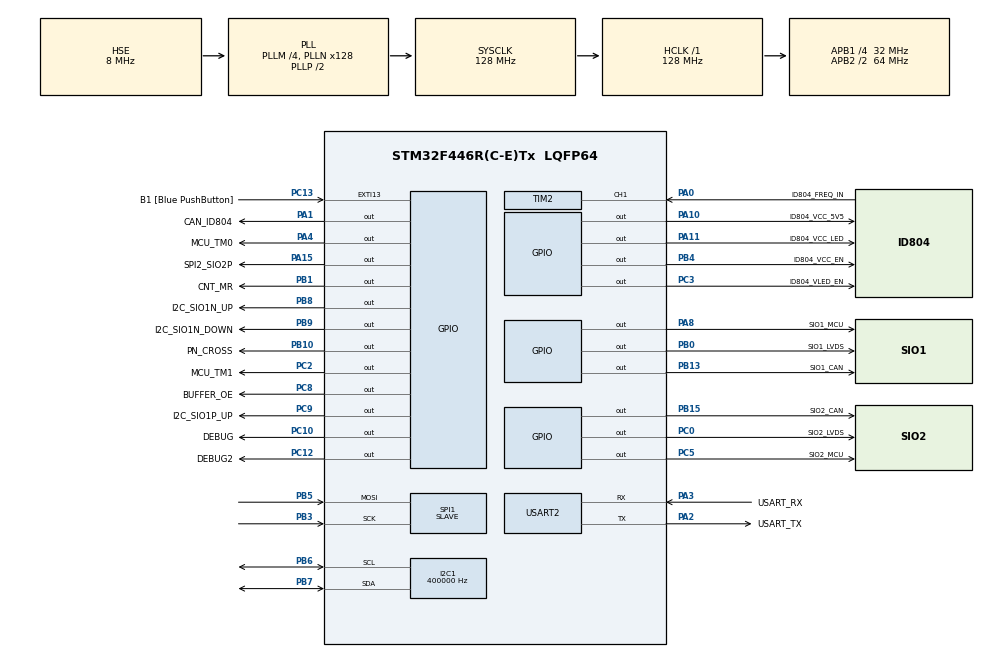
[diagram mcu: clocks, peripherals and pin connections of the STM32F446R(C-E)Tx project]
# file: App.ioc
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Dma.Request0=USART2_TX
Dma.Request1=TIM2_CH1
Dma.Request2=SPI1_RX
Dma.SPI1_RX.2.Direction=DMA_PERIPH_TO_MEMORY
Dma.SPI1_RX.2.FIFOMode=DMA_FIFOMODE_DISABLE
Dma.SPI1_RX.2.Instance=DMA2_Stream0
Dma.SPI1_RX.2.MemDataAlignment=DMA_MDATAALIGN_BYTE
Dma.SPI1_RX.2.MemInc=DMA_MINC_ENABLE
Dma.SPI1_RX.2.Mode=DMA_NORMAL
Dma.SPI1_RX.2.PeriphDataAlignment=DMA_PDATAALIGN_BYTE
Dma.SPI1_RX.2.PeriphInc=DMA_PINC_DISABLE
Dma.SPI1_RX.2.Priority=DMA_PRIORITY_LOW
Dma.TIM2_CH1.1.Direction=DMA_PERIPH_TO_MEMORY
Dma.TIM2_CH1.1.FIFOMode=DMA_FIFOMODE_DISABLE
Dma.TIM2_CH1.1.Instance=DMA1_Stream5
Dma.TIM2_CH1.1.MemDataAlignment=DMA_MDATAALIGN_WORD
Dma.TIM2_CH1.1.MemInc=DMA_MINC_ENABLE
Dma.TIM2_CH1.1.Mode=DMA_NORMAL
Dma.TIM2_CH1.1.PeriphDataAlignment=DMA_PDATAALIGN_WORD
Dma.TIM2_CH1.1.PeriphInc=DMA_PINC_DISABLE
Dma.TIM2_CH1.1.Priority=DMA_PRIORITY_LOW
Dma.USART2_TX.0.Direction=DMA_MEMORY_TO_PERIPH
Dma.USART2_TX.0.FIFOMode=DMA_FIFOMODE_DISABLE
Dma.USART2_TX.0.Instance=DMA1_Stream6
Dma.USART2_TX.0.MemDataAlignment=DMA_MDATAALIGN_BYTE
Dma.USART2_TX.0.MemInc=DMA_MINC_ENABLE
Dma.USART2_TX.0.Mode=DMA_NORMAL
Dma.USART2_TX.0.PeriphDataAlignment=DMA_PDATAALIGN_BYTE
Dma.USART2_TX.0.PeriphInc=DMA_PINC_DISABLE
Dma.USART2_TX.0.Priority=DMA_PRIORITY_LOW
FREERTOS.Tasks01=ID804Task,24,256,StartID804Task,Default,NULL,Dynamic,NULL,NULL;Debug,8,128,StartDebugTask,Default,NULL,Dynamic,NULL,NULL;CLITask,8,512,StartCLITask,Default,NULL,Dynamic,NULL,NULL
I2C1.ClockSpeed=400000
I2C1.I2C_Mode=I2C_Fast
Mcu.Family=STM32F4
Mcu.Name=STM32F446R(C-E)Tx
Mcu.Package=LQFP64
NVIC.DMA1_Stream5_IRQn=true\:5\:0\:false\:false\:true\:true\:false\:true\:true
NVIC.DMA1_Stream6_IRQn=true\:5\:0\:false\:false\:true\:true\:false\:true\:true
NVIC.DMA2_Stream0_IRQn=true\:5\:0\:false\:false\:true\:true\:false\:true\:true
NVIC.I2C1_ER_IRQn=true\:5\:0\:false\:false\:true\:true\:true\:true\:true
NVIC.I2C1_EV_IRQn=true\:5\:0\:false\:false\:true\:true\:true\:true\:true
NVIC.PriorityGroup=NVIC_PRIORITYGROUP_4
NVIC.TIM8_TRG_COM_TIM14_IRQn=true\:15\:0\:false\:false\:true\:false\:false\:true\:true
NVIC.TIM8_UP_TIM13_IRQn=true\:5\:0\:false\:false\:true\:true\:true\:true\:true
NVIC.TimeBase=TIM8_TRG_COM_TIM14_IRQn
NVIC.TimeBaseIP=TIM14
NVIC.USART2_IRQn=true\:5\:0\:false\:false\:true\:true\:true\:true\:true
PA0-WKUP.GPIO_Label=ID804_FREQ_IN
PA0-WKUP.Signal=S_TIM2_CH1_ETR
PA1.GPIO_Label=CAN_ID804
PA1.GPIO_Speed=GPIO_SPEED_FREQ_VERY_HIGH
PA1.Signal=GPIO_Output
PA10.GPIO_Label=ID804_VCC_5V5
PA10.GPIO_Speed=GPIO_SPEED_FREQ_VERY_HIGH
PA10.Signal=GPIO_Output
PA11.GPIO_Label=ID804_VCC_LED
PA11.GPIO_Speed=GPIO_SPEED_FREQ_VERY_HIGH
PA11.Signal=GPIO_Output
PA13.GPIO_Label=TMS
PA13.Mode=Serial_Wire
PA13.Signal=SYS_JTMS-SWDIO
PA14.GPIO_Label=TCK
PA14.Mode=Serial_Wire
PA14.Signal=SYS_JTCK-SWCLK
PA15.GPIO_Label=SPI2_SIO2P
PA15.GPIO_Speed=GPIO_SPEED_FREQ_VERY_HIGH
PA15.Signal=GPIO_Output
PA2.GPIO_Label=USART_TX
PA2.Mode=Asynchronous
PA2.Signal=USART2_TX
PA3.GPIO_Label=USART_RX
PA3.GPIO_PuPd=GPIO_PULLUP
PA3.Mode=Asynchronous
PA3.Signal=USART2_RX
PA4.GPIO_Label=MCU_TM0
PA4.GPIO_Speed=GPIO_SPEED_FREQ_VERY_HIGH
PA4.Signal=GPIO_Output
PA8.GPIO_Label=SIO1_MCU
PA8.GPIO_Speed=GPIO_SPEED_FREQ_VERY_HIGH
PA8.Signal=GPIO_Output
PB0.GPIO_Label=SIO1_LVDS
PB0.GPIO_Speed=GPIO_SPEED_FREQ_VERY_HIGH
PB0.Signal=GPIO_Output
PB1.GPIO_Label=CNT_MR
PB1.GPIO_Speed=GPIO_SPEED_FREQ_VERY_HIGH
PB1.PinState=GPIO_PIN_SET
PB1.Signal=GPIO_Output
PB10.GPIO_Label=PN_CROSS
PB10.GPIO_Speed=GPIO_SPEED_FREQ_VERY_HIGH
PB10.Signal=GPIO_Output
PB13.GPIO_Label=SIO1_CAN
PB13.GPIO_Speed=GPIO_SPEED_FREQ_VERY_HIGH
PB13.Signal=GPIO_Output
PB15.GPIO_Label=SIO2_CAN
PB15.GPIO_Speed=GPIO_SPEED_FREQ_VERY_HIGH
PB15.Signal=GPIO_Output
PB3.Mode=RX_Only_Simplex_Unidirect_Slave
PB3.Signal=SPI1_SCK
PB4.GPIO_Label=ID804_VCC_EN
PB4.GPIO_Speed=GPIO_SPEED_FREQ_VERY_HIGH
PB4.PinState=GPIO_PIN_SET
PB4.Signal=GPIO_Output
PB5.Mode=RX_Only_Simplex_Unidirect_Slave
PB5.Signal=SPI1_MOSI
PB6.GPIO_Pu=GPIO_NOPULL
PB6.Mode=I2C
PB6.Signal=I2C1_SCL
PB7.GPIO_Pu=GPIO_NOPULL
PB7.Mode=I2C
PB7.Signal=I2C1_SDA
PB8.GPIO_Label=I2C_SIO1N_UP
PB8.GPIO_Speed=GPIO_SPEED_FREQ_VERY_HIGH
PB8.Signal=GPIO_Output
PB9.GPIO_Label=I2C_SIO1N_DOWN
PB9.GPIO_Speed=GPIO_SPEED_FREQ_VERY_HIGH
PB9.Signal=GPIO_Output
PC0.GPIO_Label=SIO2_LVDS
PC0.GPIO_Speed=GPIO_SPEED_FREQ_VERY_HIGH
PC0.Signal=GPIO_Output
PC10.GPIO_Label=DEBUG
PC10.GPIO_Speed=GPIO_SPEED_FREQ_VERY_HIGH
PC10.Signal=GPIO_Output
PC12.GPIO_Label=DEBUG2
PC12.Signal=GPIO_Output
PC13.GPIO_Label=B1 [Blue PushButton]
PC13.GPIO_ModeDefaultEXTI=GPIO_MODE_IT_FALLING
PC13.Signal=GPXTI13
PC14-OSC32_IN.Mode=LSE-External-Oscillator
PC14-OSC32_IN.Signal=RCC_OSC32_IN
PC15-OSC32_OUT.Mode=LSE-External-Oscillator
PC15-OSC32_OUT.Signal=RCC_OSC32_OUT
PC2.GPIO_Label=MCU_TM1
PC2.GPIO_Speed=GPIO_SPEED_FREQ_VERY_HIGH
PC2.PinState=GPIO_PIN_RESET
PC2.Signal=GPIO_Output
PC3.GPIO_Label=ID804_VLED_EN
PC3.GPIO_Speed=GPIO_SPEED_FREQ_VERY_HIGH
PC3.PinState=GPIO_PIN_SET
PC3.Signal=GPIO_Output
PC5.GPIO_Label=SIO2_MCU
PC5.GPIO_Speed=GPIO_SPEED_FREQ_VERY_HIGH
PC5.Signal=GPIO_Output
PC8.GPIO_Label=BUFFER_OE
PC8.Signal=GPIO_Output
PC9.GPIO_Label=I2C_SIO1P_UP
PC9.GPIO_Speed=GPIO_SPEED_FREQ_VERY_HIGH
PC9.Signal=GPIO_Output
PH0-OSC_IN.Mode=HSE-External-Oscillator
PH0-OSC_IN.Signal=RCC_OSC_IN
PH1-OSC_OUT.Mode=HSE-External-Oscillator
PH1-OSC_OUT.Signal=RCC_OSC_OUT
ProjectManager.HeapSize=0x200
ProjectManager.StackSize=0x800
ProjectManager.TargetToolchain=EWARM V8.50
RCC.48MHZClocksFreq_Value=84000000
RCC.AHBFreq_Value=128000000
RCC.APB1CLKDivider=RCC_HCLK_DIV4
RCC.APB1Freq_Value=32000000
RCC.APB1TimFreq_Value=64000000
RCC.APB2CLKDivider=RCC_HCLK_DIV2
RCC.APB2Freq_Value=64000000
RCC.APB2TimFreq_Value=128000000
RCC.CortexFreq_Value=128000000
RCC.FLatency-AdvancedSettings=FLASH_LATENCY_4
RCC.HCLKFreq_Value=128000000
RCC.HSE_VALUE=8000000
RCC.HSI_VALUE=16000000
RCC.PLLM=4
RCC.PLLN=128
RCC.PLLSourceVirtual=RCC_PLLSOURCE_HSE
RCC.SYSCLKFreq_VALUE=128000000
RCC.SYSCLKSource=RCC_SYSCLKSOURCE_PLLCLK
RCC.USBFreq_Value=128000000
RCC.VCOOutputFreq_Value=256000000
SH.S_TIM2_CH1_ETR.0=TIM2_CH1,PWM_Input_1
SPI1.CLKPhase=SPI_PHASE_2EDGE
SPI1.Direction=SPI_DIRECTION_2LINES_RXONLY
SPI1.Mode=SPI_MODE_SLAVE
SPI1.VirtualType=VM_SLAVE
TIM13.Prescaler=63
USART2.VirtualMode=VM_ASYNC
VP_FREERTOS_VS_CMSIS_V2.Mode=CMSIS_V2
VP_SYS_VS_tim14.Mode=TIM14
VP_TIM13_VS_ClockSourceINT.Mode=Enable_Timer
VP_TIM2_VS_ClockSourceINT.Mode=Internal
board=NUCLEO-F446RE

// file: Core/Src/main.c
/* USER CODE BEGIN Header */
/**
  ******************************************************************************
  * @file           : main.c
  * @brief          : Main program body
  ******************************************************************************
  * @attention
  *
  * Copyright (c) 2026 STMicroelectronics.
  * All rights reserved.
  *
  * This software is licensed under terms that can be found in the LICENSE file
  * in the root directory of this software component.
  * If no LICENSE file comes with this software, it is provided AS-IS.
  *
  ******************************************************************************
  */
/* USER CODE END Header */
#include "main.h"
#include "cmsis_os.h"

/* USER CODE BEGIN Includes */
#include "cli.h"
#include "drv_uart.h"
#include "drv_i2c.h"
#include "drv_spi.h"
#include "drv_gpio.h"
/* USER CODE END Includes */

I2C_HandleTypeDef hi2c1;

/* Definitions for ID804Task */
osThreadId_t ID804TaskHandle;
const osThreadAttr_t ID804Task_attributes = {
  .name = "ID804Task",
  .stack_size = 256 * 4,
  .priority = (osPriority_t) osPriorityNormal,
};
/* Definitions for Debug */
osThreadId_t DebugHandle;
const osThreadAttr_t Debug_attributes = {
  .name = "Debug",
  .stack_size = 128 * 4,
  .priority = (osPriority_t) osPriorityLow,
};
/* Definitions for CLITask */
osThreadId_t CLITaskHandle;
const osThreadAttr_t CLITask_attributes = {
  .name = "CLITask",
  .stack_size = 512 * 4,
  .priority = (osPriority_t) osPriorityLow,
};

void SystemClock_Config(void);
static void MX_GPIO_Init(void);
static void MX_DMA_Init(void);
static void MX_USART2_UART_Init(void);
static void MX_SPI1_Init(void);
static void MX_I2C1_Init(void);
static void MX_TIM2_Init(void);
static void MX_TIM13_Init(void);
void StartID804Task(void *argument);
void StartDebugTask(void *argument);
void StartCLITask(void *argument);

int main(void)
{

  /* MCU Configuration--------------------------------------------------------*/

  /* Reset of all peripherals, Initializes the Flash interface and the Systick. */
  HAL_Init();

  /* Configure the system clock */
  SystemClock_Config();

  /* Initialize all configured peripherals */
  MX_GPIO_Init();
  MX_DMA_Init();
  MX_USART2_UART_Init();
  MX_SPI1_Init();
  MX_I2C1_Init();
  MX_TIM2_Init();
  MX_TIM13_Init();
  /* USER CODE BEGIN 2 */
    drv_i2c_init();
    drv_spi_init();
    drv_gpio_init();
  /* USER CODE END 2 */

  /* Init scheduler */
  osKernelInitialize();

  /* Create the thread(s) */
  /* creation of ID804Task */
  ID804TaskHandle = osThreadNew(StartID804Task, NULL, &ID804Task_attributes);

  /* creation of Debug */
  DebugHandle = osThreadNew(StartDebugTask, NULL, &Debug_attributes);

  /* creation of CLITask */
  CLITaskHandle = osThreadNew(StartCLITask, NULL, &CLITask_attributes);

  /* Start scheduler */
  osKernelStart();

  /* We should never get here as control is now taken by the scheduler */

  /* Infinite loop */
  while (1)
  {

  }
}

void SystemClock_Config(void)
{
  RCC_OscInitTypeDef RCC_OscInitStruct = {0};
  RCC_ClkInitTypeDef RCC_ClkInitStruct = {0};

  /** Configure the main internal regulator output voltage
  */
  __HAL_RCC_PWR_CLK_ENABLE();
  __HAL_PWR_VOLTAGESCALING_CONFIG(PWR_REGULATOR_VOLTAGE_SCALE2);

  /** Initializes the RCC Oscillators according to the specified parameters
  * in the RCC_OscInitTypeDef structure.
  */
  RCC_OscInitStruct.OscillatorType = RCC_OSCILLATORTYPE_HSE;
  RCC_OscInitStruct.HSEState = RCC_HSE_ON;
  RCC_OscInitStruct.PLL.PLLState = RCC_PLL_ON;
  RCC_OscInitStruct.PLL.PLLSource = RCC_PLLSOURCE_HSE;
  RCC_OscInitStruct.PLL.PLLM = 4;
  RCC_OscInitStruct.PLL.PLLN = 128;
  RCC_OscInitStruct.PLL.PLLP = RCC_PLLP_DIV2;
  RCC_OscInitStruct.PLL.PLLQ = 2;
  RCC_OscInitStruct.PLL.PLLR = 2;
  if (HAL_RCC_OscConfig(&RCC_OscInitStruct) != HAL_OK)
  {
    Error_Handler();
  }

  /** Initializes the CPU, AHB and APB buses clocks
  */
  RCC_ClkInitStruct.ClockType = RCC_CLOCKTYPE_HCLK|RCC_CLOCKTYPE_SYSCLK
                              |RCC_CLOCKTYPE_PCLK1|RCC_CLOCKTYPE_PCLK2;
  RCC_ClkInitStruct.SYSCLKSource = RCC_SYSCLKSOURCE_PLLCLK;
  RCC_ClkInitStruct.AHBCLKDivider = RCC_SYSCLK_DIV1;
  RCC_ClkInitStruct.APB1CLKDivider = RCC_HCLK_DIV4;
  RCC_ClkInitStruct.APB2CLKDivider = RCC_HCLK_DIV2;

  if (HAL_RCC_ClockConfig(&RCC_ClkInitStruct, FLASH_LATENCY_4) != HAL_OK)
  {
    Error_Handler();
  }
}

static void MX_I2C1_Init(void)
{

  hi2c1.Instance = I2C1;
  hi2c1.Init.ClockSpeed = 400000;
  hi2c1.Init.DutyCycle = I2C_DUTYCYCLE_2;
  hi2c1.Init.OwnAddress1 = 0;
  hi2c1.Init.AddressingMode = I2C_ADDRESSINGMODE_7BIT;
  hi2c1.Init.DualAddressMode = I2C_DUALADDRESS_DISABLE;
  hi2c1.Init.OwnAddress2 = 0;
  hi2c1.Init.GeneralCallMode = I2C_GENERALCALL_DISABLE;
  hi2c1.Init.NoStretchMode = I2C_NOSTRETCH_DISABLE;
  if (HAL_I2C_Init(&hi2c1) != HAL_OK)
  {
    Error_Handler();
  }

}

static void MX_SPI1_Init(void)
{

  LL_SPI_InitTypeDef SPI_InitStruct = {0};

  LL_GPIO_InitTypeDef GPIO_InitStruct = {0};

  /* Peripheral clock enable */
  LL_APB2_GRP1_EnableClock(LL_APB2_GRP1_PERIPH_SPI1);

  LL_AHB1_GRP1_EnableClock(LL_AHB1_GRP1_PERIPH_GPIOB);
  /**SPI1 GPIO Configuration
  PB3   ------> SPI1_SCK
  PB5   ------> SPI1_MOSI
  */
  GPIO_InitStruct.Pin = LL_GPIO_PIN_3|LL_GPIO_PIN_5;
  GPIO_InitStruct.Mode = LL_GPIO_MODE_ALTERNATE;
  GPIO_InitStruct.Speed = LL_GPIO_SPEED_FREQ_VERY_HIGH;
  GPIO_InitStruct.OutputType = LL_GPIO_OUTPUT_PUSHPULL;
  GPIO_InitStruct.Pull = LL_GPIO_PULL_NO;
  GPIO_InitStruct.Alternate = LL_GPIO_AF_5;
  LL_GPIO_Init(GPIOB, &GPIO_InitStruct);

  /* SPI1 DMA Init */

  /* SPI1_RX Init */
  LL_DMA_SetChannelSelection(DMA2, LL_DMA_STREAM_0, LL_DMA_CHANNEL_3);

  LL_DMA_SetDataTransferDirection(DMA2, LL_DMA_STREAM_0, LL_DMA_DIRECTION_PERIPH_TO_MEMORY);

  LL_DMA_SetStreamPriorityLevel(DMA2, LL_DMA_STREAM_0, LL_DMA_PRIORITY_LOW);

  LL_DMA_SetMode(DMA2, LL_DMA_STREAM_0, LL_DMA_MODE_NORMAL);

  LL_DMA_SetPeriphIncMode(DMA2, LL_DMA_STREAM_0, LL_DMA_PERIPH_NOINCREMENT);

  LL_DMA_SetMemoryIncMode(DMA2, LL_DMA_STREAM_0, LL_DMA_MEMORY_INCREMENT);

  LL_DMA_SetPeriphSize(DMA2, LL_DMA_STREAM_0, LL_DMA_PDATAALIGN_BYTE);

  LL_DMA_SetMemorySize(DMA2, LL_DMA_STREAM_0, LL_DMA_MDATAALIGN_BYTE);

  LL_DMA_DisableFifoMode(DMA2, LL_DMA_STREAM_0);

  /* SPI1 parameter configuration*/
  SPI_InitStruct.TransferDirection = LL_SPI_SIMPLEX_RX;
  SPI_InitStruct.Mode = LL_SPI_MODE_SLAVE;
  SPI_InitStruct.DataWidth = LL_SPI_DATAWIDTH_8BIT;
  SPI_InitStruct.ClockPolarity = LL_SPI_POLARITY_LOW;
  SPI_InitStruct.ClockPhase = LL_SPI_PHASE_2EDGE;
  SPI_InitStruct.NSS = LL_SPI_NSS_SOFT;
  SPI_InitStruct.BitOrder = LL_SPI_MSB_FIRST;
  SPI_InitStruct.CRCCalculation = LL_SPI_CRCCALCULATION_DISABLE;
  SPI_InitStruct.CRCPoly = 10;
  LL_SPI_Init(SPI1, &SPI_InitStruct);
  LL_SPI_SetStandard(SPI1, LL_SPI_PROTOCOL_MOTOROLA);

}

static void MX_TIM2_Init(void)
{

  LL_TIM_InitTypeDef TIM_InitStruct = {0};

  LL_GPIO_InitTypeDef GPIO_InitStruct = {0};

  /* Peripheral clock enable */
  LL_APB1_GRP1_EnableClock(LL_APB1_GRP1_PERIPH_TIM2);

  LL_AHB1_GRP1_EnableClock(LL_AHB1_GRP1_PERIPH_GPIOA);
  /**TIM2 GPIO Configuration
  PA0-WKUP   ------> TIM2_CH1
  */
  GPIO_InitStruct.Pin = ID804_FREQ_IN_Pin;
  GPIO_InitStruct.Mode = LL_GPIO_MODE_ALTERNATE;
  GPIO_InitStruct.Speed = LL_GPIO_SPEED_FREQ_LOW;
  GPIO_InitStruct.OutputType = LL_GPIO_OUTPUT_PUSHPULL;
  GPIO_InitStruct.Pull = LL_GPIO_PULL_NO;
  GPIO_InitStruct.Alternate = LL_GPIO_AF_1;
  LL_GPIO_Init(ID804_FREQ_IN_GPIO_Port, &GPIO_InitStruct);

  /* TIM2 DMA Init */

  /* TIM2_CH1 Init */
  LL_DMA_SetChannelSelection(DMA1, LL_DMA_STREAM_5, LL_DMA_CHANNEL_3);

  LL_DMA_SetDataTransferDirection(DMA1, LL_DMA_STREAM_5, LL_DMA_DIRECTION_PERIPH_TO_MEMORY);

  LL_DMA_SetStreamPriorityLevel(DMA1, LL_DMA_STREAM_5, LL_DMA_PRIORITY_LOW);

  LL_DMA_SetMode(DMA1, LL_DMA_STREAM_5, LL_DMA_MODE_NORMAL);

  LL_DMA_SetPeriphIncMode(DMA1, LL_DMA_STREAM_5, LL_DMA_PERIPH_NOINCREMENT);

  LL_DMA_SetMemoryIncMode(DMA1, LL_DMA_STREAM_5, LL_DMA_MEMORY_INCREMENT);

  LL_DMA_SetPeriphSize(DMA1, LL_DMA_STREAM_5, LL_DMA_PDATAALIGN_WORD);

  LL_DMA_SetMemorySize(DMA1, LL_DMA_STREAM_5, LL_DMA_MDATAALIGN_WORD);

  LL_DMA_DisableFifoMode(DMA1, LL_DMA_STREAM_5);

  TIM_InitStruct.Prescaler = 0;
  TIM_InitStruct.CounterMode = LL_TIM_COUNTERMODE_UP;
  TIM_InitStruct.Autoreload = 4294967295;
  TIM_InitStruct.ClockDivision = LL_TIM_CLOCKDIVISION_DIV1;
  LL_TIM_Init(TIM2, &TIM_InitStruct);
  LL_TIM_DisableARRPreload(TIM2);
  LL_TIM_SetClockSource(TIM2, LL_TIM_CLOCKSOURCE_INTERNAL);
  LL_TIM_SetTriggerInput(TIM2, LL_TIM_TS_TI1FP1);
  LL_TIM_SetSlaveMode(TIM2, LL_TIM_SLAVEMODE_RESET);
  LL_TIM_CC_DisableChannel(TIM2, LL_TIM_CHANNEL_CH1);
  LL_TIM_IC_SetFilter(TIM2, LL_TIM_CHANNEL_CH1, LL_TIM_IC_FILTER_FDIV1);
  LL_TIM_IC_SetPolarity(TIM2, LL_TIM_CHANNEL_CH1, LL_TIM_IC_POLARITY_RISING);
  LL_TIM_DisableIT_TRIG(TIM2);
  LL_TIM_DisableDMAReq_TRIG(TIM2);
  LL_TIM_IC_SetActiveInput(TIM2, LL_TIM_CHANNEL_CH1, LL_TIM_ACTIVEINPUT_DIRECTTI);
  LL_TIM_IC_SetPrescaler(TIM2, LL_TIM_CHANNEL_CH1, LL_TIM_ICPSC_DIV1);
  LL_TIM_IC_SetActiveInput(TIM2, LL_TIM_CHANNEL_CH2, LL_TIM_ACTIVEINPUT_INDIRECTTI);
  LL_TIM_IC_SetPrescaler(TIM2, LL_TIM_CHANNEL_CH2, LL_TIM_ICPSC_DIV1);
  LL_TIM_IC_SetFilter(TIM2, LL_TIM_CHANNEL_CH2, LL_TIM_IC_FILTER_FDIV1);
  LL_TIM_IC_SetPolarity(TIM2, LL_TIM_CHANNEL_CH2, LL_TIM_IC_POLARITY_FALLING);
  LL_TIM_SetTriggerOutput(TIM2, LL_TIM_TRGO_RESET);
  LL_TIM_DisableMasterSlaveMode(TIM2);

}

static void MX_TIM13_Init(void)
{

  LL_TIM_InitTypeDef TIM_InitStruct = {0};

  /* Peripheral clock enable */
  LL_APB1_GRP1_EnableClock(LL_APB1_GRP1_PERIPH_TIM13);

  /* TIM13 interrupt Init */
  NVIC_SetPriority(TIM8_UP_TIM13_IRQn, NVIC_EncodePriority(NVIC_GetPriorityGrouping(),5, 0));
  NVIC_EnableIRQ(TIM8_UP_TIM13_IRQn);

  TIM_InitStruct.Prescaler = 63;
  TIM_InitStruct.CounterMode = LL_TIM_COUNTERMODE_UP;
  TIM_InitStruct.Autoreload = 65535;
  TIM_InitStruct.ClockDivision = LL_TIM_CLOCKDIVISION_DIV1;
  LL_TIM_Init(TIM13, &TIM_InitStruct);
  LL_TIM_DisableARRPreload(TIM13);

}

static void MX_USART2_UART_Init(void)
{

  LL_USART_InitTypeDef USART_InitStruct = {0};

  LL_GPIO_InitTypeDef GPIO_InitStruct = {0};

  /* Peripheral clock enable */
  LL_APB1_GRP1_EnableClock(LL_APB1_GRP1_PERIPH_USART2);

  LL_AHB1_GRP1_EnableClock(LL_AHB1_GRP1_PERIPH_GPIOA);
  /**USART2 GPIO Configuration
  PA2   ------> USART2_TX
  PA3   ------> USART2_RX
  */
  GPIO_InitStruct.Pin = USART_TX_Pin;
  GPIO_InitStruct.Mode = LL_GPIO_MODE_ALTERNATE;
  GPIO_InitStruct.Speed = LL_GPIO_SPEED_FREQ_VERY_HIGH;
  GPIO_InitStruct.OutputType = LL_GPIO_OUTPUT_PUSHPULL;
  GPIO_InitStruct.Pull = LL_GPIO_PULL_NO;
  GPIO_InitStruct.Alternate = LL_GPIO_AF_7;
  LL_GPIO_Init(USART_TX_GPIO_Port, &GPIO_InitStruct);

  GPIO_InitStruct.Pin = USART_RX_Pin;
  GPIO_InitStruct.Mode = LL_GPIO_MODE_ALTERNATE;
  GPIO_InitStruct.Speed = LL_GPIO_SPEED_FREQ_VERY_HIGH;
  GPIO_InitStruct.OutputType = LL_GPIO_OUTPUT_PUSHPULL;
  GPIO_InitStruct.Pull = LL_GPIO_PULL_UP;
  GPIO_InitStruct.Alternate = LL_GPIO_AF_7;
  LL_GPIO_Init(USART_RX_GPIO_Port, &GPIO_InitStruct);

  /* USART2 DMA Init */

  /* USART2_TX Init */
  LL_DMA_SetChannelSelection(DMA1, LL_DMA_STREAM_6, LL_DMA_CHANNEL_4);

  LL_DMA_SetDataTransferDirection(DMA1, LL_DMA_STREAM_6, LL_DMA_DIRECTION_MEMORY_TO_PERIPH);

  LL_DMA_SetStreamPriorityLevel(DMA1, LL_DMA_STREAM_6, LL_DMA_PRIORITY_LOW);

  LL_DMA_SetMode(DMA1, LL_DMA_STREAM_6, LL_DMA_MODE_NORMAL);

  LL_DMA_SetPeriphIncMode(DMA1, LL_DMA_STREAM_6, LL_DMA_PERIPH_NOINCREMENT);

  LL_DMA_SetMemoryIncMode(DMA1, LL_DMA_STREAM_6, LL_DMA_MEMORY_INCREMENT);

  LL_DMA_SetPeriphSize(DMA1, LL_DMA_STREAM_6, LL_DMA_PDATAALIGN_BYTE);

  LL_DMA_SetMemorySize(DMA1, LL_DMA_STREAM_6, LL_DMA_MDATAALIGN_BYTE);

  LL_DMA_DisableFifoMode(DMA1, LL_DMA_STREAM_6);

  /* USART2 interrupt Init */
  NVIC_SetPriority(USART2_IRQn, NVIC_EncodePriority(NVIC_GetPriorityGrouping(),5, 0));
  NVIC_EnableIRQ(USART2_IRQn);

  USART_InitStruct.BaudRate = 115200;
  USART_InitStruct.DataWidth = LL_USART_DATAWIDTH_8B;
  USART_InitStruct.StopBits = LL_USART_STOPBITS_1;
  USART_InitStruct.Parity = LL_USART_PARITY_NONE;
  USART_InitStruct.TransferDirection = LL_USART_DIRECTION_TX_RX;
  USART_InitStruct.HardwareFlowControl = LL_USART_HWCONTROL_NONE;
  USART_InitStruct.OverSampling = LL_USART_OVERSAMPLING_16;
  LL_USART_Init(USART2, &USART_InitStruct);
  LL_USART_ConfigAsyncMode(USART2);
  LL_USART_Enable(USART2);

}

static void MX_DMA_Init(void)
{

  /* Init with LL driver */
  /* DMA controller clock enable */
  LL_AHB1_GRP1_EnableClock(LL_AHB1_GRP1_PERIPH_DMA1);
  LL_AHB1_GRP1_EnableClock(LL_AHB1_GRP1_PERIPH_DMA2);

  /* DMA interrupt init */
  /* DMA1_Stream5_IRQn interrupt configuration */
  NVIC_SetPriority(DMA1_Stream5_IRQn, NVIC_EncodePriority(NVIC_GetPriorityGrouping(),5, 0));
  NVIC_EnableIRQ(DMA1_Stream5_IRQn);
  /* DMA1_Stream6_IRQn interrupt configuration */
  NVIC_SetPriority(DMA1_Stream6_IRQn, NVIC_EncodePriority(NVIC_GetPriorityGrouping(),5, 0));
  NVIC_EnableIRQ(DMA1_Stream6_IRQn);
  /* DMA2_Stream0_IRQn interrupt configuration */
  NVIC_SetPriority(DMA2_Stream0_IRQn, NVIC_EncodePriority(NVIC_GetPriorityGrouping(),5, 0));
  NVIC_EnableIRQ(DMA2_Stream0_IRQn);

}

static void MX_GPIO_Init(void)
{
  LL_EXTI_InitTypeDef EXTI_InitStruct = {0};
  LL_GPIO_InitTypeDef GPIO_InitStruct = {0};

  /* GPIO Ports Clock Enable */
  LL_AHB1_GRP1_EnableClock(LL_AHB1_GRP1_PERIPH_GPIOC);
  LL_AHB1_GRP1_EnableClock(LL_AHB1_GRP1_PERIPH_GPIOH);
  LL_AHB1_GRP1_EnableClock(LL_AHB1_GRP1_PERIPH_GPIOA);
  LL_AHB1_GRP1_EnableClock(LL_AHB1_GRP1_PERIPH_GPIOB);
  LL_AHB1_GRP1_EnableClock(LL_AHB1_GRP1_PERIPH_GPIOD);

  /**/
  LL_GPIO_ResetOutputPin(GPIOC, SIO2_LVDS_Pin|MCU_TM1_Pin|SIO2_MCU_Pin|BUFFER_OE_Pin
                          |I2C_SIO1P_UP_Pin|DEBUG_Pin|DEBUG2_Pin);

  /**/
  LL_GPIO_ResetOutputPin(GPIOA, CAN_ID804_Pin|MCU_TM0_Pin|SIO1_MCU_Pin|ID804_VCC_5V5_Pin
                          |ID804_VCC_LED_Pin|SPI2_SIO2P_Pin);

  /**/
  LL_GPIO_ResetOutputPin(GPIOB, SIO1_LVDS_Pin|PN_CROSS_Pin|SIO1_CAN_Pin|SIO2_CAN_Pin
                          |I2C_SIO1N_UP_Pin|I2C_SIO1N_DOWN_Pin);

  /**/
  LL_GPIO_SetOutputPin(ID804_VLED_EN_GPIO_Port, ID804_VLED_EN_Pin);

  /**/
  LL_GPIO_SetOutputPin(GPIOB, CNT_MR_Pin|ID804_VCC_EN_Pin);

  /**/
  LL_SYSCFG_SetEXTISource(LL_SYSCFG_EXTI_PORTC, LL_SYSCFG_EXTI_LINE13);

  /**/
  EXTI_InitStruct.Line_0_31 = LL_EXTI_LINE_13;
  EXTI_InitStruct.LineCommand = ENABLE;
  EXTI_InitStruct.Mode = LL_EXTI_MODE_IT;
  EXTI_InitStruct.Trigger = LL_EXTI_TRIGGER_FALLING;
  LL_EXTI_Init(&EXTI_InitStruct);

  /**/
  LL_GPIO_SetPinPull(B1_GPIO_Port, B1_Pin, LL_GPIO_PULL_NO);

  /**/
  LL_GPIO_SetPinMode(B1_GPIO_Port, B1_Pin, LL_GPIO_MODE_INPUT);

  /**/
  GPIO_InitStruct.Pin = SIO2_LVDS_Pin|MCU_TM1_Pin|ID804_VLED_EN_Pin|SIO2_MCU_Pin
                          |I2C_SIO1P_UP_Pin|DEBUG_Pin;
  GPIO_InitStruct.Mode = LL_GPIO_MODE_OUTPUT;
  GPIO_InitStruct.Speed = LL_GPIO_SPEED_FREQ_VERY_HIGH;
  GPIO_InitStruct.OutputType = LL_GPIO_OUTPUT_PUSHPULL;
  GPIO_InitStruct.Pull = LL_GPIO_PULL_NO;
  LL_GPIO_Init(GPIOC, &GPIO_InitStruct);

  /**/
  GPIO_InitStruct.Pin = LL_GPIO_PIN_1|LL_GPIO_PIN_4|LL_GPIO_PIN_6|LL_GPIO_PIN_7
                          |LL_GPIO_PIN_11;
  GPIO_InitStruct.Mode = LL_GPIO_MODE_ANALOG;
  GPIO_InitStruct.Pull = LL_GPIO_PULL_NO;
  LL_GPIO_Init(GPIOC, &GPIO_InitStruct);

  /**/
  GPIO_InitStruct.Pin = CAN_ID804_Pin|MCU_TM0_Pin|SIO1_MCU_Pin|ID804_VCC_5V5_Pin
                          |ID804_VCC_LED_Pin|SPI2_SIO2P_Pin;
  GPIO_InitStruct.Mode = LL_GPIO_MODE_OUTPUT;
  GPIO_InitStruct.Speed = LL_GPIO_SPEED_FREQ_VERY_HIGH;
  GPIO_InitStruct.OutputType = LL_GPIO_OUTPUT_PUSHPULL;
  GPIO_InitStruct.Pull = LL_GPIO_PULL_NO;
  LL_GPIO_Init(GPIOA, &GPIO_InitStruct);

  /**/
  GPIO_InitStruct.Pin = LL_GPIO_PIN_5|LL_GPIO_PIN_6|LL_GPIO_PIN_7|LL_GPIO_PIN_9
                          |LL_GPIO_PIN_12;
  GPIO_InitStruct.Mode = LL_GPIO_MODE_ANALOG;
  GPIO_InitStruct.Pull = LL_GPIO_PULL_NO;
  LL_GPIO_Init(GPIOA, &GPIO_InitStruct);

  /**/
  GPIO_InitStruct.Pin = SIO1_LVDS_Pin|CNT_MR_Pin|PN_CROSS_Pin|SIO1_CAN_Pin
                          |SIO2_CAN_Pin|ID804_VCC_EN_Pin|I2C_SIO1N_UP_Pin|I2C_SIO1N_DOWN_Pin;
  GPIO_InitStruct.Mode = LL_GPIO_MODE_OUTPUT;
  GPIO_InitStruct.Speed = LL_GPIO_SPEED_FREQ_VERY_HIGH;
  GPIO_InitStruct.OutputType = LL_GPIO_OUTPUT_PUSHPULL;
  GPIO_InitStruct.Pull = LL_GPIO_PULL_NO;
  LL_GPIO_Init(GPIOB, &GPIO_InitStruct);

  /**/
  GPIO_InitStruct.Pin = LL_GPIO_PIN_2|LL_GPIO_PIN_12|LL_GPIO_PIN_14;
  GPIO_InitStruct.Mode = LL_GPIO_MODE_ANALOG;
  GPIO_InitStruct.Pull = LL_GPIO_PULL_NO;
  LL_GPIO_Init(GPIOB, &GPIO_InitStruct);

  /**/
  GPIO_InitStruct.Pin = BUFFER_OE_Pin|DEBUG2_Pin;
  GPIO_InitStruct.Mode = LL_GPIO_MODE_OUTPUT;
  GPIO_InitStruct.Speed = LL_GPIO_SPEED_FREQ_LOW;
  GPIO_InitStruct.OutputType = LL_GPIO_OUTPUT_PUSHPULL;
  GPIO_InitStruct.Pull = LL_GPIO_PULL_NO;
  LL_GPIO_Init(GPIOC, &GPIO_InitStruct);

  /**/
  GPIO_InitStruct.Pin = LL_GPIO_PIN_2;
  GPIO_InitStruct.Mode = LL_GPIO_MODE_ANALOG;
  GPIO_InitStruct.Pull = LL_GPIO_PULL_NO;
  LL_GPIO_Init(GPIOD, &GPIO_InitStruct);

}

void StartID804Task(void *argument)
{
  /* USER CODE BEGIN 5 */
  /* Infinite loop */
  for(;;)
  {
    osDelay(1U);
  }
  /* USER CODE END 5 */
}

void StartDebugTask(void *argument)
{
  /* USER CODE BEGIN StartDebugTask */
  /* Infinite loop */
  for(;;)
  {
    osDelay(1000U);
  }
  /* USER CODE END StartDebugTask */
}

void StartCLITask(void *argument)
{
  /* USER CODE BEGIN StartCLITask */
    drv_uart_init();
    cli_init();
  /* Infinite loop */
  for(;;)
  {
    osDelay(10U);
    cli_process();
  }
  /* USER CODE END StartCLITask */
}

void HAL_TIM_PeriodElapsedCallback(TIM_HandleTypeDef *htim)
{
  if (htim->Instance == TIM14)
  {
    HAL_IncTick();
  }
}

void Error_Handler(void)
{
  __disable_irq();
  while (1)
  {
  }
}
